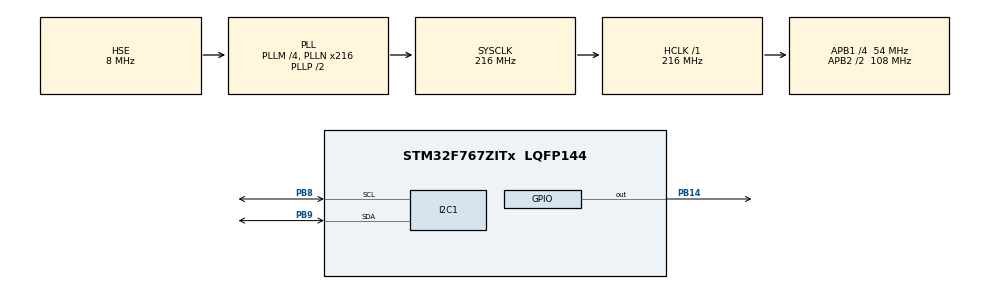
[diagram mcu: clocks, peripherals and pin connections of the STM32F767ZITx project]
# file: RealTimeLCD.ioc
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I2C1.Timing=0x20404768
Mcu.Family=STM32F7
Mcu.Name=STM32F767ZITx
Mcu.Package=LQFP144
NVIC.PriorityGroup=NVIC_PRIORITYGROUP_4
NVIC.RTC_Alarm_IRQn=true\:0\:0\:false\:false\:true\:true\:true\:true
PA13.Mode=Serial_Wire
PA13.Signal=SYS_JTMS-SWDIO
PA14.Mode=Serial_Wire
PA14.Signal=SYS_JTCK-SWCLK
PB14.Signal=GPIO_Output
PB8.Mode=I2C
PB8.Signal=I2C1_SCL
PB9.Mode=I2C
PB9.Signal=I2C1_SDA
PC14/OSC32_IN.Mode=LSE-External-Oscillator
PC14/OSC32_IN.Signal=RCC_OSC32_IN
PC15/OSC32_OUT.Mode=LSE-External-Oscillator
PC15/OSC32_OUT.Signal=RCC_OSC32_OUT
PH0/OSC_IN.Mode=HSE-External-Oscillator
PH0/OSC_IN.Signal=RCC_OSC_IN
PH1/OSC_OUT.Mode=HSE-External-Oscillator
PH1/OSC_OUT.Signal=RCC_OSC_OUT
ProjectManager.HeapSize=0x200
ProjectManager.StackSize=0x400
ProjectManager.TargetToolchain=STM32CubeIDE
RCC.48MHZClocksFreq_Value=24000000
RCC.AHBFreq_Value=216000000
RCC.APB1CLKDivider=RCC_HCLK_DIV4
RCC.APB1Freq_Value=54000000
RCC.APB1TimFreq_Value=108000000
RCC.APB2CLKDivider=RCC_HCLK_DIV2
RCC.APB2Freq_Value=108000000
RCC.APB2TimFreq_Value=216000000
RCC.CortexFreq_Value=216000000
RCC.HCLKFreq_Value=216000000
RCC.HSE_VALUE=8000000
RCC.HSI_VALUE=16000000
RCC.PLLM=4
RCC.PLLMUL=RCC_PLL_MUL9
RCC.PLLN=216
RCC.PLLQ=4
RCC.PLLSourceVirtual=RCC_PLLSOURCE_HSE
RCC.PRESCALERUSB=RCC_USBCLKSOURCE_PLL_DIV1_5
RCC.RTCClockSelection=RCC_RTCCLKSOURCE_LSE
RCC.SYSCLKFreq_VALUE=216000000
RCC.SYSCLKSource=RCC_SYSCLKSOURCE_PLLCLK
RCC.SYSCLKSourceVirtual=RCC_SYSCLKSOURCE_PLLCLK
RCC.USBFreq_Value=108000000
RCC.VCOOutputFreq_Value=432000000
RTC.Alarm-Alarm\ A=RTC_ALARM_A
RTC.AlarmDateWeekDay-Alarm\ A=27
RTC.Date=27
RTC.Hours=10
RTC.Hours_A-Alarm\ A=10
RTC.Minutes=0
RTC.Minutes_A-Alarm\ A=21
RTC.Seconds=0
VP_RTC_VS_RTC_Activate.Mode=RTC_Enabled
VP_RTC_VS_RTC_Alarm_A_Intern.Mode=Alarm A
VP_RTC_VS_RTC_Calendar.Mode=RTC_Calendar
board=NUCLEO-F767ZI

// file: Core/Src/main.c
/* USER CODE BEGIN Header */
/**
  ******************************************************************************
  * @file           : main.c
  * @brief          : Main program body
  ******************************************************************************
  * @attention
  *
  * Copyright (c) 2026 STMicroelectronics.
  * All rights reserved.
  *
  * This software is licensed under terms that can be found in the LICENSE file
  * in the root directory of this software component.
  * If no LICENSE file comes with this software, it is provided AS-IS.
  *
  ******************************************************************************
  */
/* USER CODE END Header */
#include "main.h"
#include <stdio.h>

/* USER CODE BEGIN Includes */
#include "i2c-lcd.h"
/* USER CODE END Includes */

I2C_HandleTypeDef hi2c1;

RTC_HandleTypeDef hrtc;

/* USER CODE BEGIN PV */

char time[10];
char date[10];

/* USER CODE END PV */

void SystemClock_Config(void);
static void MX_GPIO_Init(void);
static void MX_I2C1_Init(void);
static void MX_RTC_Init(void);

/* USER CODE BEGIN 0 */
void set_time (void)
{
	  RTC_TimeTypeDef sTime = {0};
	  RTC_DateTypeDef sDate = {0};
	  /** Initialize RTC and set the Time and Date
	  */
	  sTime.Hours = 0x10;
	  sTime.Minutes = 0x20;
	  sTime.Seconds = 0x30;
	  sTime.DayLightSaving = RTC_DAYLIGHTSAVING_NONE;
	  sTime.StoreOperation = RTC_STOREOPERATION_RESET;
	  if (HAL_RTC_SetTime(&hrtc, &sTime, RTC_FORMAT_BCD) != HAL_OK)
	  {
	    Error_Handler();
	  }
	  sDate.WeekDay = RTC_WEEKDAY_MONDAY;
	  sDate.Month = RTC_MONTH_JANUARY;
	  sDate.Date = 0x27;
	  sDate.Year = 0x0;
	  if (HAL_RTC_SetDate(&hrtc, &sDate, RTC_FORMAT_BCD) != HAL_OK)
	  {
	    Error_Handler();
	  }

	  HAL_RTCEx_BKUPWrite(&hrtc,RTC_BKP_DR1, 0x32F2); // Backup register to store time in-case board resets
}

void set_alarm (void)
{
	  RTC_AlarmTypeDef sAlarm = {0};
	  /** Enable the Alarm A
	  */
	  sAlarm.AlarmTime.Hours = 0x10;
	  sAlarm.AlarmTime.Minutes = 0x21;
	  sAlarm.AlarmTime.Seconds = 0x0;
	  sAlarm.AlarmTime.SubSeconds = 0x0;
	  sAlarm.AlarmTime.DayLightSaving = RTC_DAYLIGHTSAVING_NONE;
	  sAlarm.AlarmTime.StoreOperation = RTC_STOREOPERATION_RESET;
	  sAlarm.AlarmMask = RTC_ALARMMASK_NONE;
	  sAlarm.AlarmSubSecondMask = RTC_ALARMSUBSECONDMASK_ALL;
	  sAlarm.AlarmDateWeekDaySel = RTC_ALARMDATEWEEKDAYSEL_DATE;
	  sAlarm.AlarmDateWeekDay = 0x27;
	  sAlarm.Alarm = RTC_ALARM_A;
	  if (HAL_RTC_SetAlarm_IT(&hrtc, &sAlarm, RTC_FORMAT_BCD) != HAL_OK)
	  {
	    Error_Handler();
	  }
}
void get_time()
{
	RTC_DateTypeDef gDate;
	RTC_TimeTypeDef gTime;

	/* Get the RTC current Time*/
	HAL_RTC_GetTime(&hrtc, &gTime, RTC_FORMAT_BIN);
	/* Get the RTC current Date */
	HAL_RTC_GetDate(&hrtc, &gDate, RTC_FORMAT_BIN);

	/* Display time Format: hh:mm:ss */
	sprintf((char*)time,"%02d:%02d:%02d", gTime.Hours, gTime.Minutes, gTime.Seconds);

	/* Display date Format: dd-mm-yy */
	sprintf((char*)date,"%02d-%02d-%02d", gDate.Date, gDate.Month, 2026 + gDate.Year);
}

    // Time and Date Display on LCD
void display_time (void)
{
	lcd_send_cmd (0x80);
	lcd_send_string (time);
	lcd_send_cmd (0xc0);
	lcd_send_string (date);
}

/* USER CODE END 0 */

int main(void)
{

  /* MCU Configuration--------------------------------------------------------*/

  /* Reset of all peripherals, Initializes the Flash interface and the Systick. */
  HAL_Init();

  /* Configure the system clock */
  SystemClock_Config();

  /* Initialize all configured peripherals */
  MX_GPIO_Init();
  MX_I2C1_Init();
  MX_RTC_Init();
  /* USER CODE BEGIN 2 */

  lcd_init();

  if(HAL_RTCEx_BKUPRead(&hrtc, RTC_BKP_DR1) != 0x32F2)
  {
	  // Set the time
	  set_time();
  }

  set_alarm();
  /* USER CODE END 2 */

  /* Infinite loop */
  while (1)
  {

    get_time();
    display_time();
    HAL_Delay(500);

  }
}

void SystemClock_Config(void)
{
  RCC_OscInitTypeDef RCC_OscInitStruct = {0};
  RCC_ClkInitTypeDef RCC_ClkInitStruct = {0};

  /** Configure LSE Drive Capability
  */
  HAL_PWR_EnableBkUpAccess();
  __HAL_RCC_LSEDRIVE_CONFIG(RCC_LSEDRIVE_LOW);

  /** Configure the main internal regulator output voltage
  */
  __HAL_RCC_PWR_CLK_ENABLE();
  __HAL_PWR_VOLTAGESCALING_CONFIG(PWR_REGULATOR_VOLTAGE_SCALE1);

  /** Initializes the RCC Oscillators according to the specified parameters
  * in the RCC_OscInitTypeDef structure.
  */
  RCC_OscInitStruct.OscillatorType = RCC_OSCILLATORTYPE_HSE|RCC_OSCILLATORTYPE_LSE;
  RCC_OscInitStruct.HSEState = RCC_HSE_ON;
  RCC_OscInitStruct.LSEState = RCC_LSE_ON;
  RCC_OscInitStruct.PLL.PLLState = RCC_PLL_ON;
  RCC_OscInitStruct.PLL.PLLSource = RCC_PLLSOURCE_HSE;
  RCC_OscInitStruct.PLL.PLLM = 4;
  RCC_OscInitStruct.PLL.PLLN = 216;
  RCC_OscInitStruct.PLL.PLLP = RCC_PLLP_DIV2;
  RCC_OscInitStruct.PLL.PLLQ = 4;
  RCC_OscInitStruct.PLL.PLLR = 2;
  if (HAL_RCC_OscConfig(&RCC_OscInitStruct) != HAL_OK)
  {
    Error_Handler();
  }

  /** Activate the Over-Drive mode
  */
  if (HAL_PWREx_EnableOverDrive() != HAL_OK)
  {
    Error_Handler();
  }

  /** Initializes the CPU, AHB and APB buses clocks
  */
  RCC_ClkInitStruct.ClockType = RCC_CLOCKTYPE_HCLK|RCC_CLOCKTYPE_SYSCLK
                              |RCC_CLOCKTYPE_PCLK1|RCC_CLOCKTYPE_PCLK2;
  RCC_ClkInitStruct.SYSCLKSource = RCC_SYSCLKSOURCE_PLLCLK;
  RCC_ClkInitStruct.AHBCLKDivider = RCC_SYSCLK_DIV1;
  RCC_ClkInitStruct.APB1CLKDivider = RCC_HCLK_DIV4;
  RCC_ClkInitStruct.APB2CLKDivider = RCC_HCLK_DIV2;

  if (HAL_RCC_ClockConfig(&RCC_ClkInitStruct, FLASH_LATENCY_7) != HAL_OK)
  {
    Error_Handler();
  }
}

static void MX_I2C1_Init(void)
{

  hi2c1.Instance = I2C1;
  hi2c1.Init.Timing = 0x20404768;
  hi2c1.Init.OwnAddress1 = 0;
  hi2c1.Init.AddressingMode = I2C_ADDRESSINGMODE_7BIT;
  hi2c1.Init.DualAddressMode = I2C_DUALADDRESS_DISABLE;
  hi2c1.Init.OwnAddress2 = 0;
  hi2c1.Init.OwnAddress2Masks = I2C_OA2_NOMASK;
  hi2c1.Init.GeneralCallMode = I2C_GENERALCALL_DISABLE;
  hi2c1.Init.NoStretchMode = I2C_NOSTRETCH_DISABLE;
  if (HAL_I2C_Init(&hi2c1) != HAL_OK)
  {
    Error_Handler();
  }

  /** Configure Analogue filter
  */
  if (HAL_I2CEx_ConfigAnalogFilter(&hi2c1, I2C_ANALOGFILTER_ENABLE) != HAL_OK)
  {
    Error_Handler();
  }

  /** Configure Digital filter
  */
  if (HAL_I2CEx_ConfigDigitalFilter(&hi2c1, 0) != HAL_OK)
  {
    Error_Handler();
  }

}

static void MX_RTC_Init(void)
{

  /** Initialize RTC Only
  */
  hrtc.Instance = RTC;
  hrtc.Init.HourFormat = RTC_HOURFORMAT_24;
  hrtc.Init.AsynchPrediv = 127;
  hrtc.Init.SynchPrediv = 255;
  hrtc.Init.OutPut = RTC_OUTPUT_DISABLE;
  hrtc.Init.OutPutPolarity = RTC_OUTPUT_POLARITY_HIGH;
  hrtc.Init.OutPutType = RTC_OUTPUT_TYPE_OPENDRAIN;
  if (HAL_RTC_Init(&hrtc) != HAL_OK)
  {
    Error_Handler();
  }

}

static void MX_GPIO_Init(void)
{
  GPIO_InitTypeDef GPIO_InitStruct = {0};

  /* GPIO Ports Clock Enable */
  __HAL_RCC_GPIOC_CLK_ENABLE();
  __HAL_RCC_GPIOH_CLK_ENABLE();
  __HAL_RCC_GPIOB_CLK_ENABLE();
  __HAL_RCC_GPIOA_CLK_ENABLE();

  /*Configure GPIO pin Output Level */
  HAL_GPIO_WritePin(GPIOB, GPIO_PIN_14, GPIO_PIN_RESET);

  /*Configure GPIO pin : PB14 */
  GPIO_InitStruct.Pin = GPIO_PIN_14;
  GPIO_InitStruct.Mode = GPIO_MODE_OUTPUT_PP;
  GPIO_InitStruct.Pull = GPIO_NOPULL;
  GPIO_InitStruct.Speed = GPIO_SPEED_FREQ_LOW;
  HAL_GPIO_Init(GPIOB, &GPIO_InitStruct);

}

void Error_Handler(void)
{
  __disable_irq();
  while (1)
  {
  }
}
